# CEC1702 register map
Vendor: Microchip
Registers are 32-bit, read-write, reset 0x0 unless marked. A register's access mark holds for its fields unless they carry their own. Addresses are absolute, and some are shared; only a register's first bit layout is shown; [hi:lo] are bit positions; {n}, {i} and the like mark numbered series.

## CCT
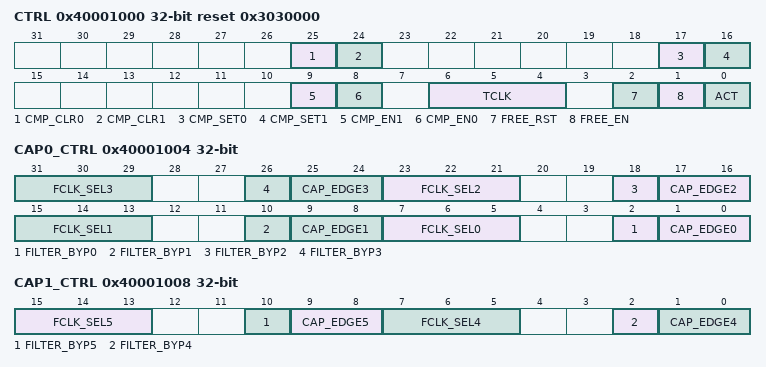
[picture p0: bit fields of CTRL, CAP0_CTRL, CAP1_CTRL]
0x40001000 CTRL reset 0x3030000
  [25] CMP_CLR0 — When read, returns the current value off the Compare Timer Output 0 state.
  [24] CMP_CLR1 — When read, returns the current value off the Compare Timer Output 1 state.
  [17] CMP_SET0 — When read, returns the current value off the Compare Timer Output 0 state.
  [16] CMP_SET1 — When read, returns the current value off the Compare Timer Output 1 state.
  [9] CMP_EN1 — Compare Enable for Compare 1 Register.
  [8] CMP_EN0 — Compare Enable for Compare 0 Register.
  [6:4] TCLK — This 3-bit field sets the clock source for the Free-Running Counter.
  [2] FREE_RST — Free Running Timer Reset. This bit stops the timer and resets the internal counter to 0000_0000h.
  [1] FREE_EN — Free-Running Timer Enable. This bit is used to start and stop the free running timer.
  [0] ACT — This bit is used to start the capture and compare timer running and power it down.
0x40001004 CAP0_CTRL
  [8n+7:8n+5] FCLK_SEL{n} (n=0..3) — This 3-bit field sets the clock source for the input filter for Capture Register {n}.
  [8n+2] FILTER_BYP{n} (n=0..3) — This bit enables bypassing the input noise filter for Capture Register {n}, so that the input signal goes directly into the timer.
  [8n+1:8n] CAP_EDGE{n} (n=0..3) — This field selects the edge type that triggers the capture of the Free Running Counter into Capture Register {n}.
0x40001008 CAP1_CTRL
  [15:13] FCLK_SEL5 — This 3-bit field sets the clock source for the input filter for Capture Register 5.
  [10] FILTER_BYP5 — This bit enables bypassing the input noise filter for Capture Register 5, so that the input signal goes directly into the timer.
  [9:8] CAP_EDGE5 — This field selects the edge type that triggers the capture of the Free Running Counter into Capture Register 5.
  [7:5] FCLK_SEL4 — This 3-bit field sets the clock source for the input filter for Capture Register 4.
  [2] FILTER_BYP4 — This bit enables bypassing the input noise filter for Capture Register 4, so that the input signal goes directly into the timer.
  [1:0] CAP_EDGE4 — This field selects the edge type that triggers the capture of the Free Running Counter into Capture Register 4.
0x4000100C FREE_RUN
  [31:0] TMR — This register contains the current value of the Free Running Timer.
{0x40001010+4i} CAP{i} (i=0..5)
  [31:0] CAP_{i} — This register saves the value copied from the Free Running timer on a programmed edge of ICT{i}.
0x40001028 COMP0
  [31:0] COMP_0 — A COMPARE 0 interrupt is generated when this register matches the value in the Free Running Timer.
0x4000102C COMP1
  [31:0] COMP_1 — A COMPARE 1 interrupt is generated when this register matches the value in the Free Running Timer.

## RC_ID0
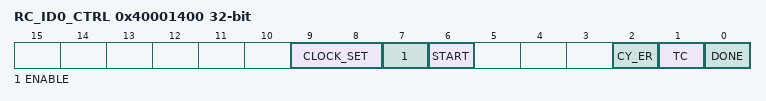
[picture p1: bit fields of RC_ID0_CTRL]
0x40001400 RC_ID0_CTRL
  [9:8] CLOCK_SET — This field selects the frequency of the Counter circuit clock. This field must retain the same value as long as the ENABLE bit in this register is 1.
  [7] ENABLE — Clearing the bit to 0 causes the RC_ID interface to enter the Reset state, gating its clocks, clearing the status bits in this register and entering into its lowest power state. Setting this bit to 1 causes the RC_ID interface to enter the Armed phase of an RC_ID measurement.
  [6] START — Setting this bit to 1 initiates the Discharged phase of an RC_ID measurement.
  [2] CY_ER — This bit is 1 if an RC_ID measurement encountered an error and the reading in the RC_ID Data Register is invalid. This bit is cleared to 0 when the RC_ID interface is in the Reset phase.
  [1] TC — This bit is cleared to 0 when the RC_ID interface is in the Reset phase, and set to 1 when the interface completes the Discharged phase of an RC_ID measurement.
  [0] DONE — This bit is cleared to 0 when the RC_ID interface is in the Reset phase, and set to 1 when the interface completes an RC_ID measurement.
0x40001404 RC_ID0_DAT
  [15:0] RCID_DATA — Reads of this register provide the result of an RC_ID measurement.
